# STM32WL33 register map
File version: 1.0
CPU: CM0+ r0p0, little endian, MPU, no FPU, 4 interrupt priority bits
Registers are 32-bit, read-write, reset 0x0 unless marked. A register's access mark holds for its fields unless they carry their own. Offsets are from the block's base; [hi:lo] are bit positions.

## MISC
Base 0x49000700
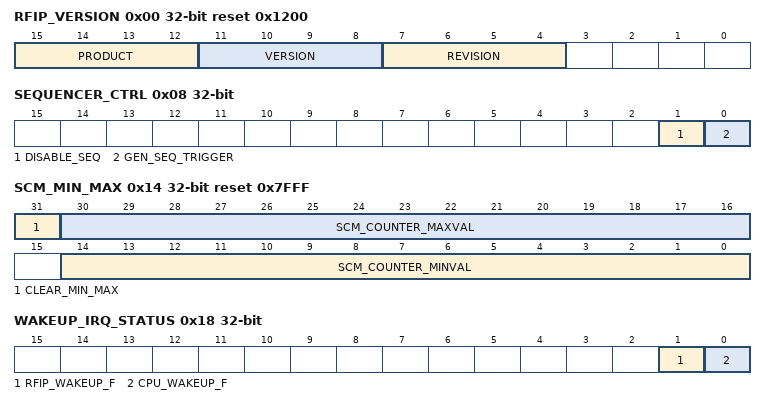
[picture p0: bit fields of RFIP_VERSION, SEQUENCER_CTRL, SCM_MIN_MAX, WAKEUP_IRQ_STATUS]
0x00 RFIP_VERSION ro reset 0x1200
  [15:12] PRODUCT — Used for major upgrades (new protocols support / new features)
  [11:8] VERSION — Version of the MR_SubG (to be used for cut upgrades)
  [7:4] REVISION — Revision of the MR_SubG (to be used for metal fixes)
0x04 RRM_UDRA_CTRL wo
  [0] RRM_CMD_REQ — Action bit: write 1 to request a RRM-UDRA command.
0x08 SEQUENCER_CTRL
  [1] DISABLE_SEQ — Enable/disable the Sequencer
  [0] GEN_SEQ_TRIGGER wo — Action bit: write 1 to generate a trigger event on Sequencer.
0x0C ABSOLUTE_TIME ro
  [31:0] ABSOLUTE_TIME — Indicate the interpolated absolute.
0x10 SCM_COUNTER_VAL ro
  [14:0] SCM_COUNTER_CURRVAL — Slow Clock Measurement: number of 16 MHz clock cycles contained in 32 slow clock periods.
0x14 SCM_MIN_MAX reset 0x7FFF
  [31] CLEAR_MIN_MAX wo — Write 1' to clear the SCM_COUNTER_MINVAL and SCM_COUNTER_MAXVAL bit fields.
  [30:16] SCM_COUNTER_MAXVAL ro — Slow Clock Measurement: maximum SCM_COUNTER value seen since the counter is ON and since last clear request.
  [14:0] SCM_COUNTER_MINVAL ro — Slow Clock Measurement: minimum SCM_COUNTER value seen since the counter is ON and since last clear request.
0x18 WAKEUP_IRQ_STATUS
  [1] RFIP_WAKEUP_F — Set when the interpolated absolute time matches the RFIP_WAKEUPTIME while WAKEUP_CTRL.
  [0] CPU_WAKEUP_F — Set when the interpolated absolute time matches the CPU_WAKEUPTIME while WAKEUP_CTRL.

## RETAINED
Base 0x49000780
0x00 RFIP_WAKEUPTIME ro
  [31:0] RFIP_WAKEUPTIME — (Absolute) Target time to wakeup the RFIP.
0x04 CPU_WAKEUPTIME
  [31:1] CPU_WAKEUPTIME — (Absolute) Target time to wakeup the CPU.
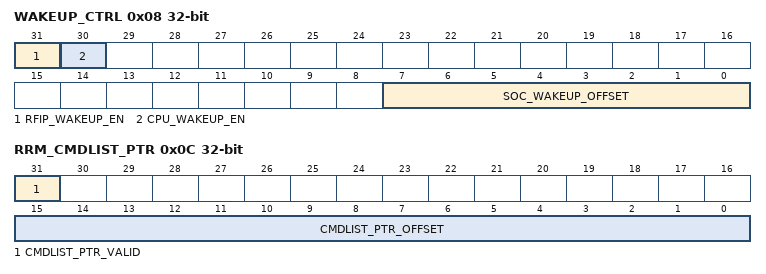
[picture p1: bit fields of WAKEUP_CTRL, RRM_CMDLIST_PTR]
0x08 WAKEUP_CTRL
  [31] RFIP_WAKEUP_EN ro — Indicates if the wakeup timer has to wakeup the SoC (match on RFIP_WAKEUPTIME[31:4] bit field only) + trigger an event on the Sequencer and set the RFIP_WAKEUP_F in the WAKEUP_IRQ_STATUS Misc register when match on RFIP_WAKEUPTIME[31:0] occurs.
  [30] CPU_WAKEUP_EN — Indicates if the wakeup timer has to wakeup the SoC (match on CPU_WAKEUPTIME[31:4] bit field only) + set the CPU_WAKEUP_F in the WAKEUP_IRQ_STATUS Misc register when match on CPU_WAKEUPTIME[31:0] occurs.
  [7:0] SOC_WAKEUP_OFFSET — Delay to be considered by the Wakeup block to anticipate the wakeup request to the PWRC of the SoC versus the target to wakeup the RFIP (or the CPU).
0x0C RRM_CMDLIST_PTR
  [31] CMDLIST_PTR_VALID — Indicate if a command list has to be executed or not
  [15:0] CMDLIST_PTR_OFFSET — Contain the offset versus the SoC RAM base address where to find the RRM-UDRA command list entry point.
0x10 SEQ_GLOBALTABLE_PTR
  [15:0] SEQ_GLOBALTABLE_PTR — Contain the offset versus the SoC RAM base address of the GlobalConfiguration RAM table entry point.

## RNG
Base 0x48600000
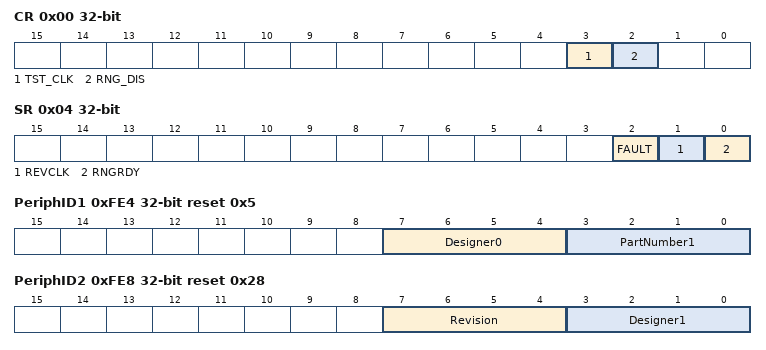
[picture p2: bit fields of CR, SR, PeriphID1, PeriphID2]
0x00 CR — RNG_CR register
  [3] TST_CLK — RNG Test Clock bit.
  [2] RNG_DIS — RNG Disable bit.
0x04 SR — RNG_SR register
  [2] FAULT — Fault Reveal bit.
  [1] REVCLK ro — RNGCLK Clock Reveal bit.
  [0] RNGRDY ro — New Random Value Ready.
0x08 VAL ro — RNG_VAL register
  [15:0] RANDOM_VALUE
0x80 TCR — RNG_TCR register
  [0] TCR — Test-control register
0x84 ITIP — RNG_ITIP register
  [0] ITIP — Integration-test input register
0xFE0 PeriphID0 ro reset 0xE1 — RNGPeriphID0 register
  [7:0] PartNumber0 — These bits are read back as 0xE1
0xFE4 PeriphID1 ro reset 0x5 — RNGPeriphID1 register
  [7:4] Designer0 — These bits are read back as 0x00
  [3:0] PartNumber1 — These bits are read back as 0x05
0xFE8 PeriphID2 ro reset 0x28 — RNGPeriphID2 register
  [7:4] Revision — These bits are read back as 0x02
  [3:0] Designer1 — These bits are read back as 0x08
0xFEC PeriphID3 ro — RNGPeriphID3 register
  [7:0] Configuration — These bits are read back as 0x00
0xFF0 PCellID0 ro reset 0xD — RNGPCellID0 register
  [7:0] RNGPCellID0 — These bits are read back as 0x0D
0xFF4 PCellID1 ro reset 0xF0 — RNGPCellID1 register
  [7:0] RNGPCellID1 — These bits are read back as 0xF0
0xFF8 PCellID2 ro reset 0x5 — RNGPCellID2 register
  [7:0] RNGPCellID2 — These bits are read back as 0x05
0xFFC PCellID3 ro reset 0xB1 — RNGPCellID3 register
  [7:0] RNGPCellID3 — These bits are read back as 0xB1

## SWITCHABLE
Base 0x49001040
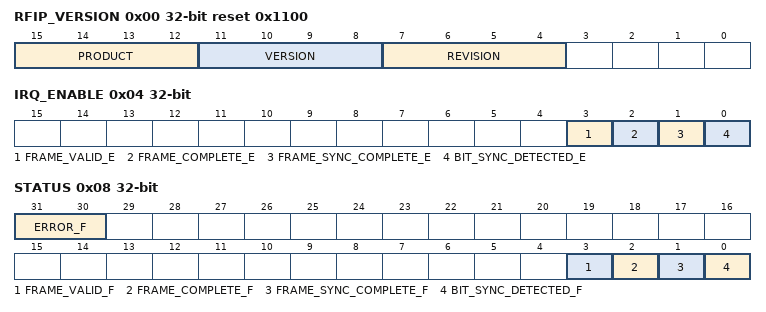
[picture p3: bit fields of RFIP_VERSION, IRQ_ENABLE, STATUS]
0x00 RFIP_VERSION ro reset 0x1100
  [15:12] PRODUCT — Used for major upgrades (new protocols support / new features)
  [11:8] VERSION — Version of the RFIP (to be used for cut upgrades)
  [7:4] REVISION — Revision of the RFIP to be used for metal fixes)
0x04 IRQ_ENABLE
  [3] FRAME_VALID_E — Frame ( payload + CRC) received wthout error (the CRC has been checked and is matching with the received CRC).
  [2] FRAME_COMPLETE_E — Frame ( payload + CRC) received, the content of the PAYLOAD_X registers is valid.
  [1] FRAME_SYNC_COMPLETE_E — Frame Sync has been detected, the content of the PAYLOAD_X registers is not yet valid.
  [0] BIT_SYNC_DETECTED_E — Preamble has been detected, the content of the PAYLOAD_X registers is not yet valid.
0x08 STATUS
  [31:30] ERROR_F — - 11 : CRC error
  [3] FRAME_VALID_F — Frame ( payload + CRC) received wthout error (the CRC has been checked and is matching with the received CRC).
  [2] FRAME_COMPLETE_F — Frame ( payload + CRC) received, the content of the PAYLOAD_X registers is valid.
  [1] FRAME_SYNC_COMPLETE_F — Frame Sync has been detected, the content of the PAYLOAD_X registers is not yet valid.
  [0] BIT_SYNC_DETECTED_F — Preamble has been detected, the content of the PAYLOAD_X registers is not yet valid.
